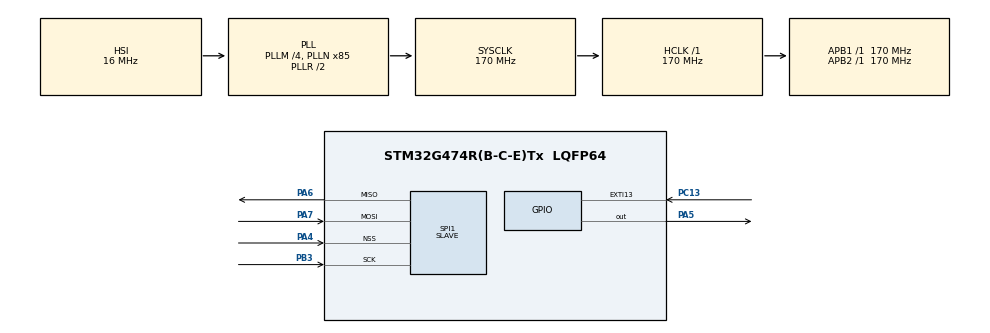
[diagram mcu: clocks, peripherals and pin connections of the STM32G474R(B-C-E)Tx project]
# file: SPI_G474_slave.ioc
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Mcu.Family=STM32G4
Mcu.Name=STM32G474R(B-C-E)Tx
Mcu.Package=LQFP64
NUCLEO-G474RE.BUTTON=1
NUCLEO-G474RE.LD2=true
NUCLEO-G474RE.VCP=true
NVIC.EXTI15_10_IRQn=true\:0\:0\:false\:false\:true\:true\:true\:true
NVIC.PriorityGroup=NVIC_PRIORITYGROUP_4
PA13.GPIO_Label=T_SWDIO
PA13.Signal=SYS_JTMS-SWDIO
PA14.GPIO_Label=T_SWCLK
PA14.Signal=SYS_JTCK-SWCLK
PA2.Signal=LPUART1_TX
PA3.Signal=LPUART1_RX
PA4.Mode=NSS_Signal_Hard_Input
PA4.Signal=SPI1_NSS
PA5.Signal=GPIO_Output
PA6.Mode=Full_Duplex_Slave
PA6.Signal=SPI1_MISO
PA7.Mode=Full_Duplex_Slave
PA7.Signal=SPI1_MOSI
PB3.Mode=Full_Duplex_Slave
PB3.Signal=SPI1_SCK
PC13.Signal=GPXTI13
PC14-OSC32_IN.GPIO_Label=RCC_OSC32_IN
PC14-OSC32_IN.Signal=RCC_OSC32_IN
PC15-OSC32_OUT.GPIO_Label=RCC_OSC32_OUT
PC15-OSC32_OUT.Signal=RCC_OSC32_OUT
PF0-OSC_IN.GPIO_Label=RCC_OSC_IN
PF0-OSC_IN.Signal=RCC_OSC_IN
PF1-OSC_OUT.GPIO_Label=RCC_OSC_OUT
PF1-OSC_OUT.Signal=RCC_OSC_OUT
ProjectManager.HeapSize=0x200
ProjectManager.StackSize=0x400
ProjectManager.TargetToolchain=STM32CubeIDE
RCC.ADC12Freq_Value=170000000
RCC.ADC345Freq_Value=170000000
RCC.AHBFreq_Value=170000000
RCC.APB1Freq_Value=170000000
RCC.APB1TimFreq_Value=170000000
RCC.APB2Freq_Value=170000000
RCC.APB2TimFreq_Value=170000000
RCC.CortexFreq_Value=170000000
RCC.EXTERNAL_CLOCK_VALUE=12288000
RCC.HCLKFreq_Value=170000000
RCC.HSE_VALUE=24000000
RCC.HSI48_VALUE=48000000
RCC.HSI_VALUE=16000000
RCC.LSE_VALUE=32768
RCC.PLLM=RCC_PLLM_DIV4
RCC.PLLN=85
RCC.RTCClockSelection=RCC_RTCCLKSOURCE_LSE
RCC.SYSCLKFreq_VALUE=170000000
RCC.SYSCLKSource=RCC_SYSCLKSOURCE_PLLCLK
RCC.USBFreq_Value=170000000
RCC.VCOOutputFreq_Value=340000000
SPI1.DataSize=SPI_DATASIZE_8BIT
SPI1.Direction=SPI_DIRECTION_2LINES
SPI1.Mode=SPI_MODE_SLAVE
SPI1.VirtualNSS=VM_NSSHARD
SPI1.VirtualType=VM_SLAVE
VP_NUCLEO-G474RE_VS_BSP_COMMON.Mode=COMMON
VP_SYS_VS_DBSignals.Mode=DisableDeadBatterySignals
board=NUCLEO-G474RE

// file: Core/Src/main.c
/* USER CODE BEGIN Header */
/**
  ******************************************************************************
  * @file           : main.c
  * @brief          : Main program body
  ******************************************************************************
  * @attention
  *
  * Copyright (c) 2025 STMicroelectronics.
  * All rights reserved.
  *
  * This software is licensed under terms that can be found in the LICENSE file
  * in the root directory of this software component.
  * If no LICENSE file comes with this software, it is provided AS-IS.
  *
  ******************************************************************************
  */
/* USER CODE END Header */
#include "main.h"

COM_InitTypeDef BspCOMInit;
SPI_HandleTypeDef hspi1;

void SystemClock_Config(void);
static void MX_GPIO_Init(void);
static void MX_SPI1_Init(void);

int main(void)
{

  /* MCU Configuration--------------------------------------------------------*/

  /* Reset of all peripherals, Initializes the Flash interface and the Systick. */
  HAL_Init();

  /* Configure the system clock */
  SystemClock_Config();

  /* Initialize all configured peripherals */
  MX_GPIO_Init();
  MX_SPI1_Init();
  /* USER CODE BEGIN 2 */
  // Master로부터 수신할 데이터를 저장할 변수입니다.
  uint8_t rx_data;
  /* USER CODE END 2 */

  /* Initialize led */
  BSP_LED_Init(LED_GREEN);

  /* Initialize USER push-button, will be used to trigger an interrupt each time it's pressed.*/
  BSP_PB_Init(BUTTON_USER, BUTTON_MODE_EXTI);

  /* Initialize COM1 port (115200, 8 bits (7-bit data + 1 stop bit), no parity */
  BspCOMInit.BaudRate   = 115200;
  BspCOMInit.WordLength = COM_WORDLENGTH_8B;
  BspCOMInit.StopBits   = COM_STOPBITS_1;
  BspCOMInit.Parity     = COM_PARITY_NONE;
  BspCOMInit.HwFlowCtl  = COM_HWCONTROL_NONE;
  if (BSP_COM_Init(COM1, &BspCOMInit) != BSP_ERROR_NONE)
  {
    Error_Handler();
  }

  /* Infinite loop */
  while (1)
  {

    /* USER CODE BEGIN 3 */
    // Master로부터 1바이트 데이터가 수신되기를 기다립니다.
    if (HAL_SPI_Receive(&hspi1, &rx_data, 1, HAL_MAX_DELAY) == HAL_OK)
    {
      // 수신된 데이터에 따라 LED(PA5)를 제어합니다.
      if (rx_data == '1')
      {
        // '1'을 받으면 LED를 켭니다.
        HAL_GPIO_WritePin(GPIOA, GPIO_PIN_5, GPIO_PIN_SET);
      }
      else if (rx_data == '0')
      {
        // '0'을 받으면 LED를 끕니다.
        HAL_GPIO_WritePin(GPIOA, GPIO_PIN_5, GPIO_PIN_RESET);
      }
    }
  }
  /* USER CODE END 3 */
}

void SystemClock_Config(void)
{
  RCC_OscInitTypeDef RCC_OscInitStruct = {0};
  RCC_ClkInitTypeDef RCC_ClkInitStruct = {0};

  /** Configure the main internal regulator output voltage
  */
  HAL_PWREx_ControlVoltageScaling(PWR_REGULATOR_VOLTAGE_SCALE1_BOOST);

  /** Initializes the RCC Oscillators according to the specified parameters
  * in the RCC_OscInitTypeDef structure.
  */
  RCC_OscInitStruct.OscillatorType = RCC_OSCILLATORTYPE_HSI;
  RCC_OscInitStruct.HSIState = RCC_HSI_ON;
  RCC_OscInitStruct.HSICalibrationValue = RCC_HSICALIBRATION_DEFAULT;
  RCC_OscInitStruct.PLL.PLLState = RCC_PLL_ON;
  RCC_OscInitStruct.PLL.PLLSource = RCC_PLLSOURCE_HSI;
  RCC_OscInitStruct.PLL.PLLM = RCC_PLLM_DIV4;
  RCC_OscInitStruct.PLL.PLLN = 85;
  RCC_OscInitStruct.PLL.PLLP = RCC_PLLP_DIV2;
  RCC_OscInitStruct.PLL.PLLQ = RCC_PLLQ_DIV2;
  RCC_OscInitStruct.PLL.PLLR = RCC_PLLR_DIV2;
  if (HAL_RCC_OscConfig(&RCC_OscInitStruct) != HAL_OK)
  {
    Error_Handler();
  }

  /** Initializes the CPU, AHB and APB buses clocks
  */
  RCC_ClkInitStruct.ClockType = RCC_CLOCKTYPE_HCLK|RCC_CLOCKTYPE_SYSCLK
                              |RCC_CLOCKTYPE_PCLK1|RCC_CLOCKTYPE_PCLK2;
  RCC_ClkInitStruct.SYSCLKSource = RCC_SYSCLKSOURCE_PLLCLK;
  RCC_ClkInitStruct.AHBCLKDivider = RCC_SYSCLK_DIV1;
  RCC_ClkInitStruct.APB1CLKDivider = RCC_HCLK_DIV1;
  RCC_ClkInitStruct.APB2CLKDivider = RCC_HCLK_DIV1;

  if (HAL_RCC_ClockConfig(&RCC_ClkInitStruct, FLASH_LATENCY_4) != HAL_OK)
  {
    Error_Handler();
  }
}

static void MX_SPI1_Init(void)
{

  /* SPI1 parameter configuration*/
  hspi1.Instance = SPI1;
  hspi1.Init.Mode = SPI_MODE_SLAVE;
  hspi1.Init.Direction = SPI_DIRECTION_2LINES;
  hspi1.Init.DataSize = SPI_DATASIZE_8BIT;
  hspi1.Init.CLKPolarity = SPI_POLARITY_LOW;
  hspi1.Init.CLKPhase = SPI_PHASE_1EDGE;
  hspi1.Init.NSS = SPI_NSS_HARD_INPUT;
  hspi1.Init.FirstBit = SPI_FIRSTBIT_MSB;
  hspi1.Init.TIMode = SPI_TIMODE_DISABLE;
  hspi1.Init.CRCCalculation = SPI_CRCCALCULATION_DISABLE;
  hspi1.Init.CRCPolynomial = 7;
  hspi1.Init.CRCLength = SPI_CRC_LENGTH_DATASIZE;
  hspi1.Init.NSSPMode = SPI_NSS_PULSE_DISABLE;
  if (HAL_SPI_Init(&hspi1) != HAL_OK)
  {
    Error_Handler();
  }

}

static void MX_GPIO_Init(void)
{

  /* GPIO Ports Clock Enable */
  __HAL_RCC_GPIOC_CLK_ENABLE();
  __HAL_RCC_GPIOF_CLK_ENABLE();
  __HAL_RCC_GPIOA_CLK_ENABLE();
  __HAL_RCC_GPIOB_CLK_ENABLE();

}

void Error_Handler(void)
{
  __disable_irq();
  while (1)
  {
  }
}
